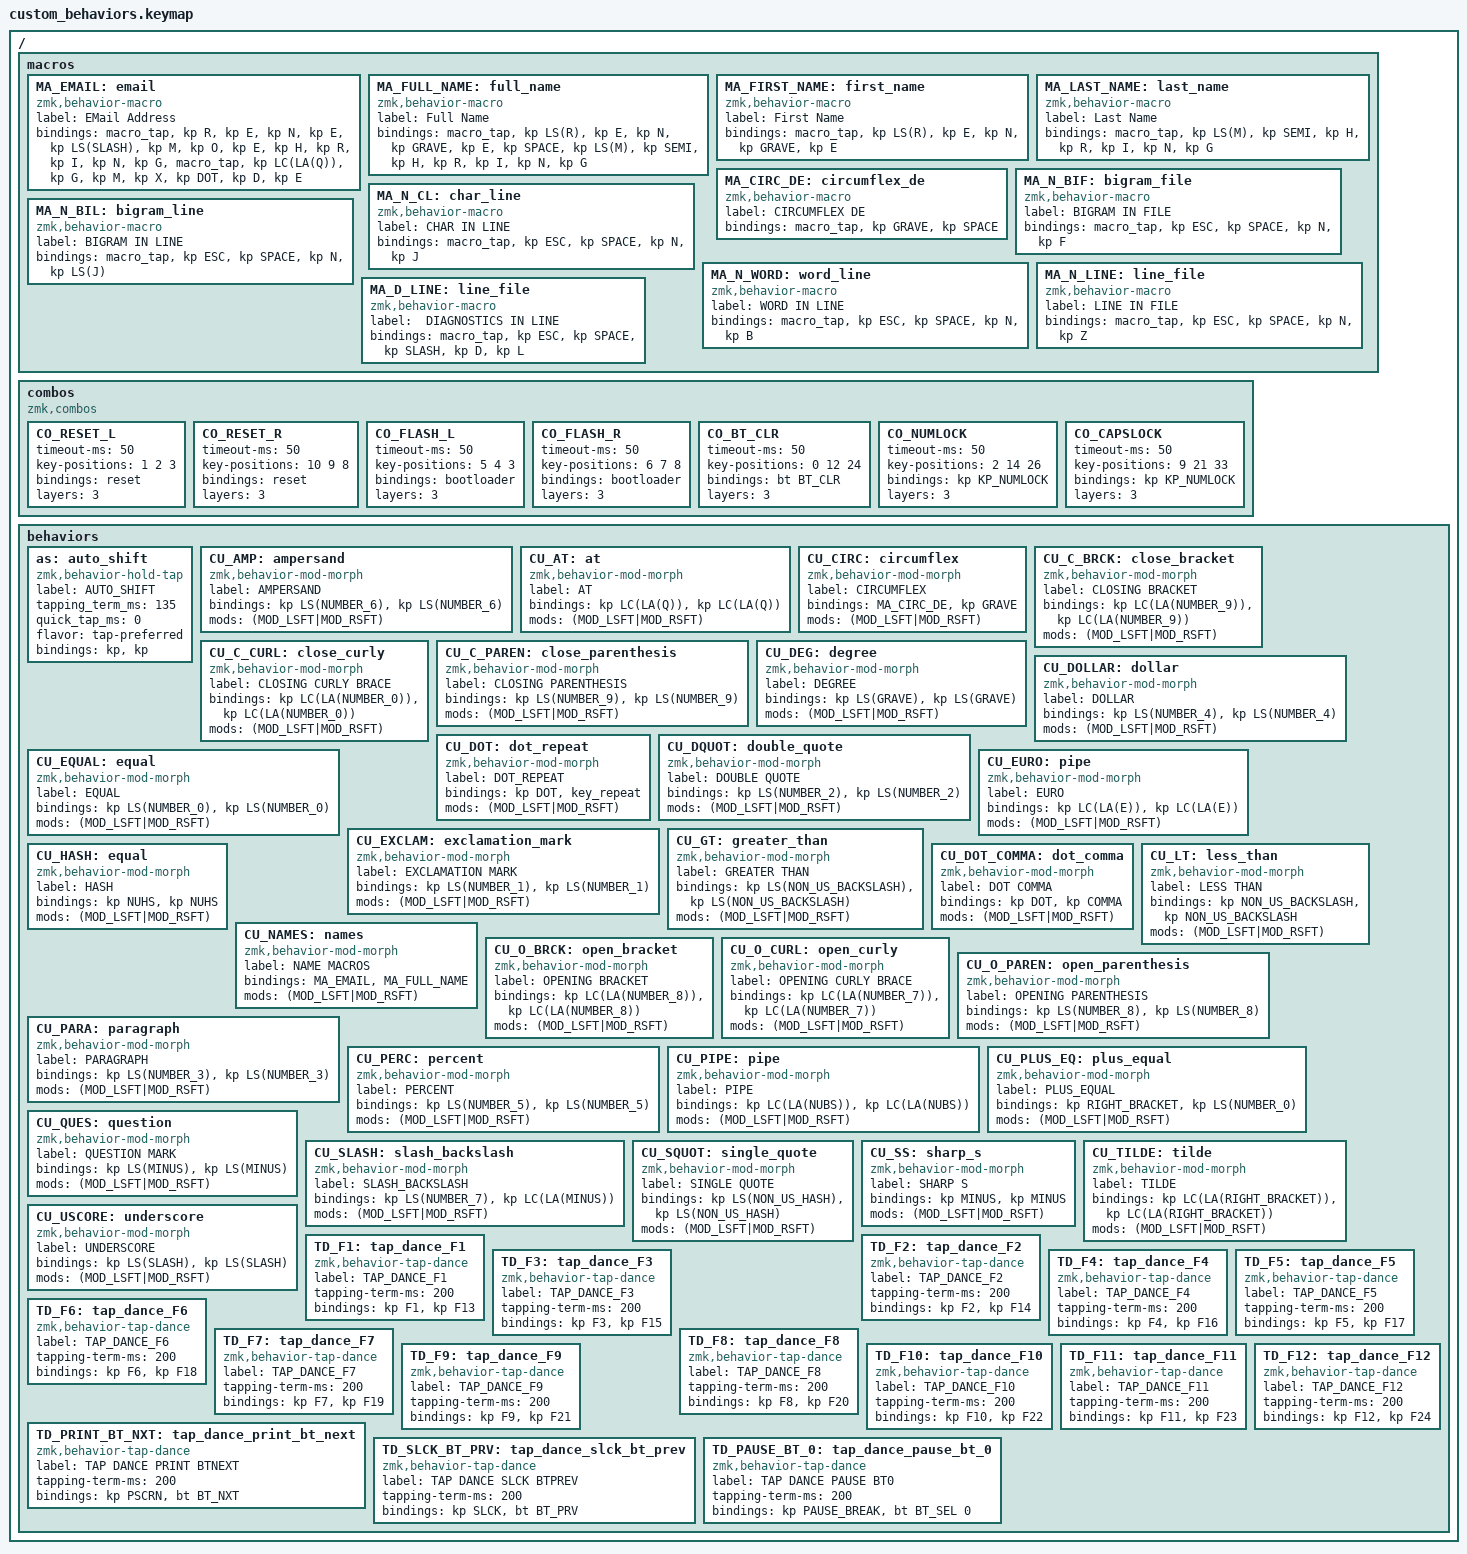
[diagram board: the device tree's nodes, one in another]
#include <dt-bindings/zmk/bt.h>

/ {
    macros {
      MA_EMAIL: email {
        compatible = "zmk,behavior-macro";
        label = "EMail Address";
        #binding-cells = <0>;
        bindings =  <&macro_tap &kp R &kp E &kp N &kp E &kp LS(SLASH) &kp M &kp O &kp E &kp H &kp R &kp I &kp N &kp G>
                   ,<&macro_tap &kp LC(LA(Q)) &kp G &kp M &kp X &kp DOT &kp D &kp E >;
      };
      MA_FULL_NAME: full_name {
        compatible = "zmk,behavior-macro";
        label = "Full Name";
        #binding-cells = <0>;
        bindings =  <&macro_tap &kp LS(R) &kp E &kp N &kp GRAVE &kp E &kp SPACE &kp LS(M) &kp SEMI &kp H &kp R &kp I &kp N &kp G>;
      };
      MA_FIRST_NAME: first_name {
        compatible = "zmk,behavior-macro";
        label = "First Name";
        #binding-cells = <0>;
        bindings =  <&macro_tap &kp LS(R) &kp E &kp N &kp GRAVE &kp E>;
      };
      MA_LAST_NAME: last_name {
        compatible = "zmk,behavior-macro";
        label = "Last Name";
        #binding-cells = <0>;
        bindings =  <&macro_tap &kp LS(M) &kp SEMI &kp H &kp R &kp I &kp N &kp G>;
      };
      MA_CIRC_DE: circumflex_de {
        compatible = "zmk,behavior-macro";
        label = "CIRCUMFLEX DE";
        #binding-cells = <0>;
        bindings = <&macro_tap &kp GRAVE &kp SPACE>;
      };
      MA_N_BIF: bigram_file {
        compatible = "zmk,behavior-macro";
        label = "BIGRAM IN FILE";
        #binding-cells = <0>;
        bindings = <&macro_tap &kp ESC &kp SPACE &kp N &kp F>;
      };
      MA_N_CL: char_line {
        compatible = "zmk,behavior-macro";
        label = "CHAR IN LINE";
        #binding-cells = <0>;
        bindings = <&macro_tap &kp ESC &kp SPACE &kp N &kp J>;
      };
      MA_N_BIL: bigram_line {
        compatible = "zmk,behavior-macro";
        label = "BIGRAM IN LINE";
        #binding-cells = <0>;
        bindings = <&macro_tap &kp ESC &kp SPACE &kp N &kp LS(J)>;
      };
      MA_N_WORD: word_line {
        compatible = "zmk,behavior-macro";
        label = "WORD IN LINE";
        #binding-cells = <0>;
        bindings = <&macro_tap &kp ESC &kp SPACE &kp N &kp B>;
      };
      MA_N_LINE: line_file {
        compatible = "zmk,behavior-macro";
        label = "LINE IN FILE";
        #binding-cells = <0>;
        bindings = <&macro_tap &kp ESC &kp SPACE &kp N &kp Z>;
      };
      MA_D_LINE: line_file {
        compatible = "zmk,behavior-macro";
        label = " DIAGNOSTICS IN LINE";
        #binding-cells = <0>;
        bindings = <&macro_tap &kp ESC &kp SPACE &kp SLASH &kp D &kp L>;
      };
    };
  };

/ {
    combos {
      compatible = "zmk,combos";
      CO_RESET_L {
        timeout-ms = <50>;
        key-positions = <1 2 3>;
        bindings = <&reset>;
        layers = <3>;
      };
      CO_RESET_R {
        timeout-ms = <50>;
        key-positions = <10 9 8>;
        bindings = <&reset>;
        layers = <3>;
      };
      CO_FLASH_L {
        timeout-ms = <50>;
        key-positions = <5 4 3>;
        bindings = <&bootloader>;
        layers = <3>;
      };
      CO_FLASH_R {
        timeout-ms = <50>;
        key-positions = <6 7 8>;
        bindings = <&bootloader>;
        layers = <3>;
      };
      CO_BT_CLR {
        timeout-ms = <50>;
        key-positions = <0 12 24>;
        bindings = <&bt BT_CLR>;
        layers = <3>;
      };
      CO_NUMLOCK {
        timeout-ms = <50>;
        key-positions = <2 14 26>;
        bindings = <&kp KP_NUMLOCK>;
        layers = <3>;
      };
      CO_CAPSLOCK {
        timeout-ms = <50>;
        key-positions = <9 21 33>;
        bindings = <&kp KP_NUMLOCK>;
        layers = <3>;
      };
    };
};

/ {
  behaviors {
    as: auto_shift {
      compatible = "zmk,behavior-hold-tap";
      label = "AUTO_SHIFT";
      #binding-cells = <2>;
      tapping_term_ms = <135>;
      quick_tap_ms = <0>;
      flavor = "tap-preferred";
      bindings = <&kp>, <&kp>;
    };
    CU_AMP: ampersand {
      compatible = "zmk,behavior-mod-morph";
      label = "AMPERSAND";
      #binding-cells = <0>;
      bindings = <&kp LS(NUMBER_6)>, <&kp LS(NUMBER_6)>;
      mods = <(MOD_LSFT|MOD_RSFT)>;
    };
    CU_AT: at {
      compatible = "zmk,behavior-mod-morph";
      label = "AT";
      #binding-cells = <0>;
      bindings = <&kp LC(LA(Q))>, <&kp LC(LA(Q))>;
      mods = <(MOD_LSFT|MOD_RSFT)>;
    };
    CU_CIRC: circumflex {
      compatible = "zmk,behavior-mod-morph";
      label = "CIRCUMFLEX";
      #binding-cells = <0>;
      bindings = <&MA_CIRC_DE>, <&kp GRAVE>;
      mods = <(MOD_LSFT|MOD_RSFT)>;
    };
    CU_C_BRCK: close_bracket {
      compatible = "zmk,behavior-mod-morph";
      label = "CLOSING BRACKET";
      #binding-cells = <0>;
      bindings = <&kp LC(LA(NUMBER_9))>, <&kp LC(LA(NUMBER_9))>;
      mods = <(MOD_LSFT|MOD_RSFT)>;
    };
    CU_C_CURL: close_curly {
      compatible = "zmk,behavior-mod-morph";
      label = "CLOSING CURLY BRACE";
      #binding-cells = <0>;
      bindings = <&kp LC(LA(NUMBER_0))>, <&kp LC(LA(NUMBER_0))>;
      mods = <(MOD_LSFT|MOD_RSFT)>;
    };
    CU_C_PAREN: close_parenthesis {
      compatible = "zmk,behavior-mod-morph";
      label = "CLOSING PARENTHESIS";
      #binding-cells = <0>;
      bindings = <&kp LS(NUMBER_9)>, <&kp LS(NUMBER_9)>;
      mods = <(MOD_LSFT|MOD_RSFT)>;
    };
    CU_DEG: degree{
      compatible = "zmk,behavior-mod-morph";
      label = "DEGREE";
      #binding-cells = <0>;
      bindings = <&kp LS(GRAVE)>, <&kp LS(GRAVE)>;
      mods = <(MOD_LSFT|MOD_RSFT)>;
    };
    CU_DOLLAR: dollar{
      compatible = "zmk,behavior-mod-morph";
      label = "DOLLAR";
      #binding-cells = <0>;
      bindings = <&kp LS(NUMBER_4)>, <&kp LS(NUMBER_4)>;
      mods = <(MOD_LSFT|MOD_RSFT)>;
    };
    CU_DOT: dot_repeat {
      compatible = "zmk,behavior-mod-morph";
      label = "DOT_REPEAT";
      #binding-cells = <0>;
      bindings = <&kp DOT>, <&key_repeat>;
      mods = <(MOD_LSFT|MOD_RSFT)>;
    };
    CU_DQUOT: double_quote {
      compatible = "zmk,behavior-mod-morph";
      label = "DOUBLE QUOTE";
      #binding-cells = <0>;
      bindings = <&kp LS(NUMBER_2)>, <&kp LS(NUMBER_2)>;
      mods = <(MOD_LSFT|MOD_RSFT)>;
    };
    CU_EQUAL: equal {
      compatible = "zmk,behavior-mod-morph";
      label = "EQUAL";
      #binding-cells = <0>;
      bindings = <&kp LS(NUMBER_0)>, <&kp LS(NUMBER_0)>;
      mods = <(MOD_LSFT|MOD_RSFT)>;
    };
    CU_EURO: pipe {
      compatible = "zmk,behavior-mod-morph";
      label = "EURO";
      #binding-cells = <0>;
      bindings = <&kp LC(LA(E))>, <&kp LC(LA(E))>;
      mods = <(MOD_LSFT|MOD_RSFT)>;
    };
    CU_EXCLAM: exclamation_mark {
      compatible = "zmk,behavior-mod-morph";
      label = "EXCLAMATION MARK";
      #binding-cells = <0>;
      bindings = <&kp LS(NUMBER_1)>, <&kp LS(NUMBER_1)>;
      mods = <(MOD_LSFT|MOD_RSFT)>;
    };
    CU_GT: greater_than {
      compatible = "zmk,behavior-mod-morph";
      label = "GREATER THAN";
      #binding-cells = <0>;
      bindings = <&kp LS(NON_US_BACKSLASH)>, <&kp LS(NON_US_BACKSLASH)>;
      mods = <(MOD_LSFT|MOD_RSFT)>;
    };
    CU_HASH: equal {
      compatible = "zmk,behavior-mod-morph";
      label = "HASH";
      #binding-cells = <0>;
      bindings = <&kp NUHS>, <&kp NUHS>;
      mods = <(MOD_LSFT|MOD_RSFT)>;
    };
    CU_DOT_COMMA: dot_comma {
      compatible = "zmk,behavior-mod-morph";
      label = "DOT COMMA";
      #binding-cells = <0>;
      bindings = <&kp DOT>, <&kp COMMA>;
      mods = <(MOD_LSFT|MOD_RSFT)>;
    };
    CU_LT: less_than {
      compatible = "zmk,behavior-mod-morph";
      label = "LESS THAN";
      #binding-cells = <0>;
      bindings = <&kp NON_US_BACKSLASH>, <&kp NON_US_BACKSLASH>;
      mods = <(MOD_LSFT|MOD_RSFT)>;
    };
    CU_NAMES: names {
      compatible = "zmk,behavior-mod-morph";
      label = "NAME MACROS";
      #binding-cells = <0>;
      bindings = <&MA_EMAIL>, <&MA_FULL_NAME>;
      mods = <(MOD_LSFT|MOD_RSFT)>;
    };
    CU_O_BRCK: open_bracket {
      compatible = "zmk,behavior-mod-morph";
      label = "OPENING BRACKET";
      #binding-cells = <0>;
      bindings = <&kp LC(LA(NUMBER_8))>, <&kp LC(LA(NUMBER_8))>;
      mods = <(MOD_LSFT|MOD_RSFT)>;
    };
    CU_O_CURL: open_curly {
      compatible = "zmk,behavior-mod-morph";
      label = "OPENING CURLY BRACE";
      #binding-cells = <0>;
      bindings = <&kp LC(LA(NUMBER_7))>, <&kp LC(LA(NUMBER_7))>;
      mods = <(MOD_LSFT|MOD_RSFT)>;
    };
    CU_O_PAREN: open_parenthesis {
      compatible = "zmk,behavior-mod-morph";
      label = "OPENING PARENTHESIS";
      #binding-cells = <0>;
      bindings = <&kp LS(NUMBER_8)>, <&kp LS(NUMBER_8)>;
      mods = <(MOD_LSFT|MOD_RSFT)>;
    };
    CU_PARA: paragraph {
      compatible = "zmk,behavior-mod-morph";
      label = "PARAGRAPH";
      #binding-cells = <0>;
      bindings = <&kp LS(NUMBER_3)>, <&kp LS(NUMBER_3)>;
      mods = <(MOD_LSFT|MOD_RSFT)>;
    };
    CU_PERC: percent {
      compatible = "zmk,behavior-mod-morph";
      label = "PERCENT";
      #binding-cells = <0>;
      bindings = <&kp LS(NUMBER_5)>, <&kp LS(NUMBER_5)>;
      mods = <(MOD_LSFT|MOD_RSFT)>;
    };
    CU_PIPE: pipe {
      compatible = "zmk,behavior-mod-morph";
      label = "PIPE";
      #binding-cells = <0>;
      bindings = <&kp LC(LA(NUBS))>, <&kp LC(LA(NUBS))>;
      mods = <(MOD_LSFT|MOD_RSFT)>;
    };
    CU_PLUS_EQ: plus_equal {
      compatible = "zmk,behavior-mod-morph";
      label = "PLUS_EQUAL";
      #binding-cells = <0>;
      bindings = <&kp RIGHT_BRACKET>, <&kp LS(NUMBER_0)>;
      mods = <(MOD_LSFT|MOD_RSFT)>;
    };
    CU_QUES: question {
      compatible = "zmk,behavior-mod-morph";
      label = "QUESTION MARK";
      #binding-cells = <0>;
      bindings = <&kp LS(MINUS)>, <&kp LS(MINUS)>;
      mods = <(MOD_LSFT|MOD_RSFT)>;
    };
    CU_SLASH: slash_backslash {
      compatible = "zmk,behavior-mod-morph";
      label = "SLASH_BACKSLASH";
      #binding-cells = <0>;
      bindings = <&kp LS(NUMBER_7)>, <&kp LC(LA(MINUS))>;
      mods = <(MOD_LSFT|MOD_RSFT)>;
    };
    CU_SQUOT: single_quote {
      compatible = "zmk,behavior-mod-morph";
      label = "SINGLE QUOTE";
      #binding-cells = <0>;
      bindings = <&kp LS(NON_US_HASH)>, <&kp LS(NON_US_HASH)>;
      mods = <(MOD_LSFT|MOD_RSFT)>;
    };
    CU_SS: sharp_s {
      compatible = "zmk,behavior-mod-morph";
      label = "SHARP S";
      #binding-cells = <0>;
      bindings = <&kp MINUS>, <&kp MINUS>;
      mods = <(MOD_LSFT|MOD_RSFT)>;
    };
    CU_TILDE: tilde {
      compatible = "zmk,behavior-mod-morph";
      label = "TILDE";
      #binding-cells = <0>;
      bindings = <&kp LC(LA(RIGHT_BRACKET))>, <&kp LC(LA(RIGHT_BRACKET))>;
      mods = <(MOD_LSFT|MOD_RSFT)>;
    };
    CU_USCORE: underscore {
      compatible = "zmk,behavior-mod-morph";
      label = "UNDERSCORE";
      #binding-cells = <0>;
      bindings = <&kp LS(SLASH)>, <&kp LS(SLASH)>;
      mods = <(MOD_LSFT|MOD_RSFT)>;
    };
    TD_F1: tap_dance_F1 {
      compatible = "zmk,behavior-tap-dance";
      label = "TAP_DANCE_F1";
      #binding-cells = <0>;
      tapping-term-ms = <200>;
      bindings = <&kp F1>, <&kp F13>;
    };
    TD_F2: tap_dance_F2 {
      compatible = "zmk,behavior-tap-dance";
      label = "TAP_DANCE_F2";
      #binding-cells = <0>;
      tapping-term-ms = <200>;
      bindings = <&kp F2>, <&kp F14>;
    };
    TD_F3: tap_dance_F3 {
      compatible = "zmk,behavior-tap-dance";
      label = "TAP_DANCE_F3";
      #binding-cells = <0>;
      tapping-term-ms = <200>;
      bindings = <&kp F3>, <&kp F15>;
    };
    TD_F4: tap_dance_F4 {
      compatible = "zmk,behavior-tap-dance";
      label = "TAP_DANCE_F4";
      #binding-cells = <0>;
      tapping-term-ms = <200>;
      bindings = <&kp F4>, <&kp F16>;
    };
    TD_F5: tap_dance_F5 {
      compatible = "zmk,behavior-tap-dance";
      label = "TAP_DANCE_F5";
      #binding-cells = <0>;
      tapping-term-ms = <200>;
      bindings = <&kp F5>, <&kp F17>;
    };
    TD_F6: tap_dance_F6 {
      compatible = "zmk,behavior-tap-dance";
      label = "TAP_DANCE_F6";
      #binding-cells = <0>;
      tapping-term-ms = <200>;
      bindings = <&kp F6>, <&kp F18>;
    };
    TD_F7: tap_dance_F7 {
      compatible = "zmk,behavior-tap-dance";
      label = "TAP_DANCE_F7";
      #binding-cells = <0>;
      tapping-term-ms = <200>;
      bindings = <&kp F7>, <&kp F19>;
    };
    TD_F8: tap_dance_F8 {
      compatible = "zmk,behavior-tap-dance";
      label = "TAP_DANCE_F8";
      #binding-cells = <0>;
      tapping-term-ms = <200>;
      bindings = <&kp F8>, <&kp F20>;
    };
    TD_F9: tap_dance_F9 {
      compatible = "zmk,behavior-tap-dance";
      label = "TAP_DANCE_F9";
      #binding-cells = <0>;
      tapping-term-ms = <200>;
      bindings = <&kp F9>, <&kp F21>;
    };
    TD_F10: tap_dance_F10 {
      compatible = "zmk,behavior-tap-dance";
      label = "TAP_DANCE_F10";
      #binding-cells = <0>;
      tapping-term-ms = <200>;
      bindings = <&kp F10>, <&kp F22>;
    };
    TD_F11: tap_dance_F11 {
      compatible = "zmk,behavior-tap-dance";
      label = "TAP_DANCE_F11";
      #binding-cells = <0>;
      tapping-term-ms = <200>;
      bindings = <&kp F11>, <&kp F23>;
    };
    TD_F12: tap_dance_F12 {
      compatible = "zmk,behavior-tap-dance";
      label = "TAP_DANCE_F12";
      #binding-cells = <0>;
      tapping-term-ms = <200>;
      bindings = <&kp F12>, <&kp F24>;
    };
    TD_PRINT_BT_NXT: tap_dance_print_bt_next {
      compatible = "zmk,behavior-tap-dance";
      label = "TAP DANCE PRINT BTNEXT";
      #binding-cells = <0>;
      tapping-term-ms = <200>;
      bindings = <&kp PSCRN>, <&bt BT_NXT>;
    };
    TD_SLCK_BT_PRV: tap_dance_slck_bt_prev {
      compatible = "zmk,behavior-tap-dance";
      label = "TAP DANCE SLCK BTPREV";
      #binding-cells = <0>;
      tapping-term-ms = <200>;
      bindings = <&kp SLCK>, <&bt BT_PRV>;
    };
    TD_PAUSE_BT_0: tap_dance_pause_bt_0 {
      compatible = "zmk,behavior-tap-dance";
      label = "TAP DANCE PAUSE BT0";
      #binding-cells = <0>;
      tapping-term-ms = <200>;
      bindings = <&kp PAUSE_BREAK>, <&bt BT_SEL 0>;
    };
  };
};

// Autoshift

#define AS(keycode) &as LS(keycode) keycode

// Symbols
#define AS_CIRC &as &MA_CIRC_DE GRAVE
#define AS_DOT &as DOT &key_repeat
#define AS_DOT_COMMA &as COMMA DOT
#define AS_NAMES &as LS(&CU_NAMES) &CU_NAMES
#define AS_PLUS_EQ &as LS(NUMBER_0) RIGHT_BRACKET
#define AS_SLASH &as KP_SLASH LC(LA(MINUS))

#define AS_AMP &CU_AMP
#define AS_AE AS(SINGLE_QUOTE)
#define AS_AT &CU_AT
#define AS_C_BRCK &CU_C_BRCK
#define AS_C_CURL &CU_C_CURL
#define AS_C_PAREN &CU_C_PAREN
#define AS_DEG &CU_DEG
#define AS_DOLLAR &CU_DOLLAR
#define AS_DQUOT &CU_DQUOT
#define AS_EQUAL &CU_EQUAL
#define AS_EURO &CU_EURO
#define AS_EXCLAM &CU_EXCLAM
#define AS_GRAVE AS(EQUAL)
#define AS_GT &CU_GT
#define AS_HASH &CU_HASH
#define AS_LT &CU_LT
#define AS_LT &CU_LT
#define AS_OE AS(SEMICOLON)
#define AS_O_BRCK &CU_O_BRCK
#define AS_O_CURL &CU_O_CURL
#define AS_O_PAREN &CU_O_PAREN
#define AS_PARA &CU_PARA
#define AS_PERC &CU_PERC
#define AS_PIPE &CU_PIPE
#define AS_QUES &CU_QUES
#define AS_SQUOT &CU_SQUOT
#define AS_SS &CU_SS
#define AS_TILDE &CU_TILDE
#define AS_UE AS(LEFT_BRACKET)
#define AS_USCORE &CU_USCORE

// vim :set expandtab
